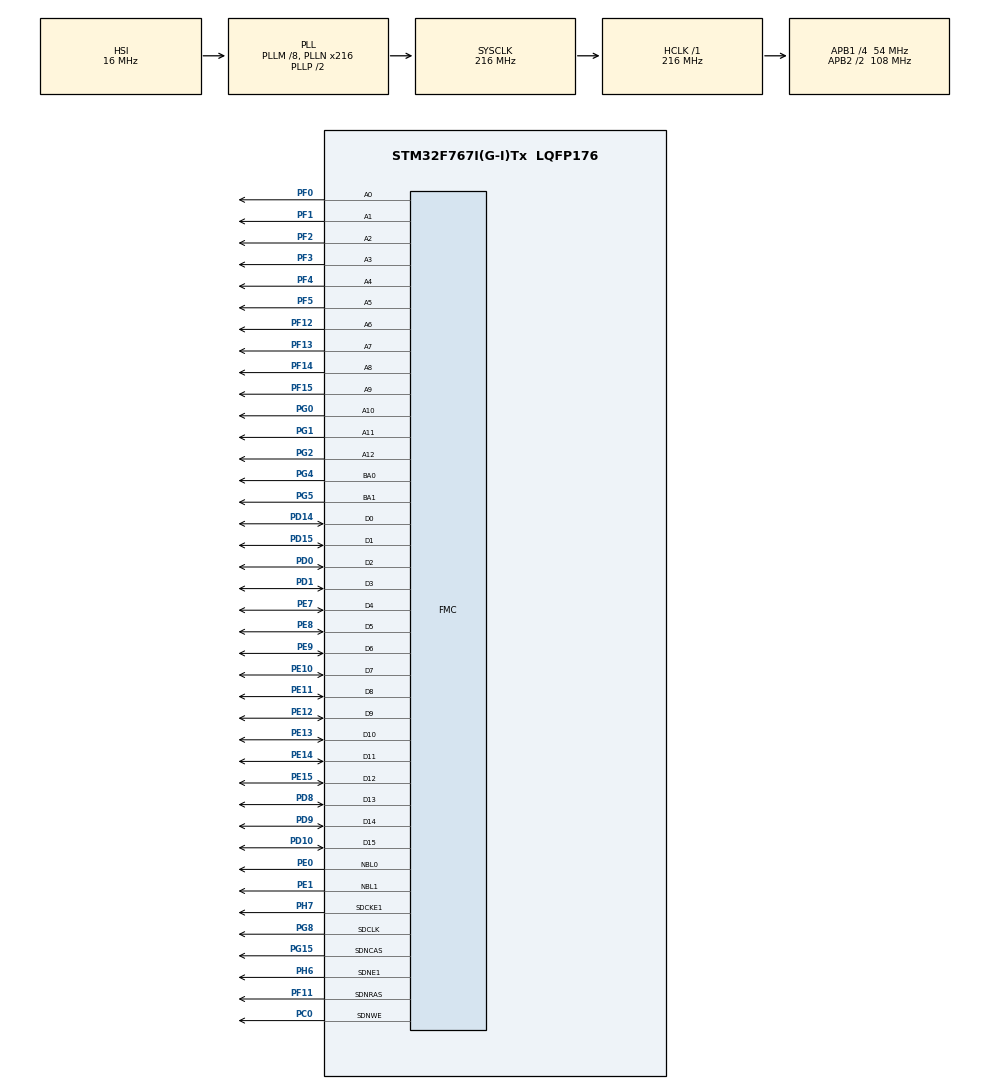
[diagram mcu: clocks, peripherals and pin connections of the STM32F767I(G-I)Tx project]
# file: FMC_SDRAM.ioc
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FMC.CASLatency2=FMC_SDRAM_CAS_LATENCY_3
FMC.ColumnBitsNumber2=FMC_SDRAM_COLUMN_BITS_NUM_9
FMC.ExitSelfRefreshDelay2=9
FMC.LoadToActiveDelay2=2
FMC.RCDDelay2=3
FMC.RPDelay1=3
FMC.RPDelay2=3
FMC.RowCycleDelay1=8
FMC.RowCycleDelay2=8
FMC.SDClockPeriod1=FMC_SDRAM_CLOCK_PERIOD_2
FMC.SDClockPeriod2=FMC_SDRAM_CLOCK_PERIOD_2
FMC.SelfRefreshTime2=6
FMC.WriteRecoveryTime2=3
Mcu.Family=STM32F7
Mcu.Name=STM32F767I(G-I)Tx
Mcu.Package=LQFP176
NVIC.PriorityGroup=NVIC_PRIORITYGROUP_4
PA13.Mode=Serial_Wire
PA13.Signal=SYS_JTMS-SWDIO
PA14.Mode=Serial_Wire
PA14.Signal=SYS_JTCK-SWCLK
PC0.Signal=FMC_SDNWE
PD0.Signal=FMC_D2_DA2
PD1.Signal=FMC_D3_DA3
PD10.Signal=FMC_D15_DA15
PD14.Signal=FMC_D0_DA0
PD15.Signal=FMC_D1_DA1
PD8.Signal=FMC_D13_DA13
PD9.Signal=FMC_D14_DA14
PE0.Signal=FMC_NBL0
PE1.Signal=FMC_NBL1
PE10.Signal=FMC_D7_DA7
PE11.Signal=FMC_D8_DA8
PE12.Signal=FMC_D9_DA9
PE13.Signal=FMC_D10_DA10
PE14.Signal=FMC_D11_DA11
PE15.Signal=FMC_D12_DA12
PE7.Signal=FMC_D4_DA4
PE8.Signal=FMC_D5_DA5
PE9.Signal=FMC_D6_DA6
PF0.Signal=FMC_A0
PF1.Signal=FMC_A1
PF11.Signal=FMC_SDNRAS
PF12.Signal=FMC_A6
PF13.Signal=FMC_A7
PF14.Signal=FMC_A8
PF15.Signal=FMC_A9
PF2.Signal=FMC_A2
PF3.Signal=FMC_A3
PF4.Signal=FMC_A4
PF5.Signal=FMC_A5
PG0.Signal=FMC_A10
PG1.Signal=FMC_A11
PG15.Signal=FMC_SDNCAS
PG2.Signal=FMC_A12
PG4.Signal=FMC_A14_BA0
PG5.Signal=FMC_A15_BA1
PG8.Signal=FMC_SDCLK
PH0/OSC_IN.Mode=HSE-External-Oscillator
PH0/OSC_IN.Signal=RCC_OSC_IN
PH1/OSC_OUT.Mode=HSE-External-Oscillator
PH1/OSC_OUT.Signal=RCC_OSC_OUT
PH6.Mode=SdramChipSelect2_2
PH6.Signal=FMC_SDNE1
PH7.Mode=SdramChipSelect2_2
PH7.Signal=FMC_SDCKE1
ProjectManager.HeapSize=0x200
ProjectManager.StackSize=0x400
ProjectManager.TargetToolchain=MDK-ARM V5.32
RCC.AHBFreq_Value=216000000
RCC.APB1CLKDivider=RCC_HCLK_DIV4
RCC.APB1Freq_Value=54000000
RCC.APB1TimFreq_Value=108000000
RCC.APB2CLKDivider=RCC_HCLK_DIV2
RCC.APB2Freq_Value=108000000
RCC.APB2TimFreq_Value=216000000
RCC.CortexFreq_Value=216000000
RCC.HCLKFreq_Value=216000000
RCC.HSE_VALUE=25000000
RCC.HSI_VALUE=16000000
RCC.LSE_VALUE=32768
RCC.PLLM=8
RCC.PLLN=216
RCC.SYSCLKFreq_VALUE=216000000
RCC.SYSCLKSource=RCC_SYSCLKSOURCE_PLLCLK
RCC.USBFreq_Value=216000000
RCC.VCOOutputFreq_Value=432000000
SH.FMC_A0.0=FMC_A0,13b-sda2
SH.FMC_A1.0=FMC_A1,13b-sda2
SH.FMC_A10.0=FMC_A10,13b-sda2
SH.FMC_A11.0=FMC_A11,13b-sda2
SH.FMC_A12.0=FMC_A12,13b-sda2
SH.FMC_A14_BA0.0=FMC_BA0,FourSdramBanks2
SH.FMC_A15_BA1.0=FMC_BA1,FourSdramBanks2
SH.FMC_A2.0=FMC_A2,13b-sda2
SH.FMC_A3.0=FMC_A3,13b-sda2
SH.FMC_A4.0=FMC_A4,13b-sda2
SH.FMC_A5.0=FMC_A5,13b-sda2
SH.FMC_A6.0=FMC_A6,13b-sda2
SH.FMC_A7.0=FMC_A7,13b-sda2
SH.FMC_A8.0=FMC_A8,13b-sda2
SH.FMC_A9.0=FMC_A9,13b-sda2
SH.FMC_D0_DA0.0=FMC_D0,sd-16b-d2
SH.FMC_D10_DA10.0=FMC_D10,sd-16b-d2
SH.FMC_D11_DA11.0=FMC_D11,sd-16b-d2
SH.FMC_D12_DA12.0=FMC_D12,sd-16b-d2
SH.FMC_D13_DA13.0=FMC_D13,sd-16b-d2
SH.FMC_D14_DA14.0=FMC_D14,sd-16b-d2
SH.FMC_D15_DA15.0=FMC_D15,sd-16b-d2
SH.FMC_D1_DA1.0=FMC_D1,sd-16b-d2
SH.FMC_D2_DA2.0=FMC_D2,sd-16b-d2
SH.FMC_D3_DA3.0=FMC_D3,sd-16b-d2
SH.FMC_D4_DA4.0=FMC_D4,sd-16b-d2
SH.FMC_D5_DA5.0=FMC_D5,sd-16b-d2
SH.FMC_D6_DA6.0=FMC_D6,sd-16b-d2
SH.FMC_D7_DA7.0=FMC_D7,sd-16b-d2
SH.FMC_D8_DA8.0=FMC_D8,sd-16b-d2
SH.FMC_D9_DA9.0=FMC_D9,sd-16b-d2
SH.FMC_NBL0.0=FMC_NBL0,Sd2ByteEnable2
SH.FMC_NBL1.0=FMC_NBL1,Sd2ByteEnable2
SH.FMC_SDCLK.0=FMC_SDCLK,13b-sda2
SH.FMC_SDNCAS.0=FMC_SDNCAS,13b-sda2
SH.FMC_SDNRAS.0=FMC_SDNRAS,13b-sda2
SH.FMC_SDNWE.0=FMC_SDNWE,13b-sda2
board=custom

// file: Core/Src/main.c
/* USER CODE BEGIN Header */
/**
  ******************************************************************************
  * @file           : main.c
  * @brief          : Main program body
  ******************************************************************************
  * @attention
  *
  * Copyright (c) 2023 STMicroelectronics.
  * All rights reserved.
  *
  * This software is licensed under terms that can be found in the LICENSE file
  * in the root directory of this software component.
  * If no LICENSE file comes with this software, it is provided AS-IS.
  *
  ******************************************************************************
  */
/* USER CODE END Header */
#include "main.h"
#include "gpio.h"
#include "fmc.h"

void SystemClock_Config(void);
static void MPU_Config(void);

/* USER CODE BEGIN 0 */
uint32_t pbuff[(32*1024*1024)/4] __attribute__((at(0xD0000000)));

/* USER CODE END 0 */

int main(void)
{

  /* MPU Configuration--------------------------------------------------------*/
  MPU_Config();

  /* MCU Configuration--------------------------------------------------------*/

  /* Reset of all peripherals, Initializes the Flash interface and the Systick. */
  HAL_Init();

  /* Configure the system clock */
  SystemClock_Config();

  /* Initialize all configured peripherals */
  MX_GPIO_Init();
  MX_FMC_Init();
  /* USER CODE BEGIN 2 */

	for(int count =0;count<0x20000000/4;count++)
		pbuff[count] = count;

	for(int count =0;count<0x20000000/4;count++)
	{
		if(pbuff[count] != count)
		{
			goto checkFailed;
		}
	}

  /* USER CODE END 2 */

  /* Infinite loop */
  while (1)
  {

    /* USER CODE BEGIN 3 */
  }
checkFailed:
	while(1);
  /* USER CODE END 3 */
}

void SystemClock_Config(void)
{
  RCC_OscInitTypeDef RCC_OscInitStruct = {0};
  RCC_ClkInitTypeDef RCC_ClkInitStruct = {0};

  /** Configure the main internal regulator output voltage
  */
  __HAL_RCC_PWR_CLK_ENABLE();
  __HAL_PWR_VOLTAGESCALING_CONFIG(PWR_REGULATOR_VOLTAGE_SCALE1);

  /** Initializes the RCC Oscillators according to the specified parameters
  * in the RCC_OscInitTypeDef structure.
  */
  RCC_OscInitStruct.OscillatorType = RCC_OSCILLATORTYPE_HSI;
  RCC_OscInitStruct.HSIState = RCC_HSI_ON;
  RCC_OscInitStruct.HSICalibrationValue = RCC_HSICALIBRATION_DEFAULT;
  RCC_OscInitStruct.PLL.PLLState = RCC_PLL_ON;
  RCC_OscInitStruct.PLL.PLLSource = RCC_PLLSOURCE_HSI;
  RCC_OscInitStruct.PLL.PLLM = 8;
  RCC_OscInitStruct.PLL.PLLN = 216;
  RCC_OscInitStruct.PLL.PLLP = RCC_PLLP_DIV2;
  RCC_OscInitStruct.PLL.PLLQ = 2;
  RCC_OscInitStruct.PLL.PLLR = 2;
  if (HAL_RCC_OscConfig(&RCC_OscInitStruct) != HAL_OK)
  {
    Error_Handler();
  }

  /** Activate the Over-Drive mode
  */
  if (HAL_PWREx_EnableOverDrive() != HAL_OK)
  {
    Error_Handler();
  }

  /** Initializes the CPU, AHB and APB buses clocks
  */
  RCC_ClkInitStruct.ClockType = RCC_CLOCKTYPE_HCLK|RCC_CLOCKTYPE_SYSCLK
                              |RCC_CLOCKTYPE_PCLK1|RCC_CLOCKTYPE_PCLK2;
  RCC_ClkInitStruct.SYSCLKSource = RCC_SYSCLKSOURCE_PLLCLK;
  RCC_ClkInitStruct.AHBCLKDivider = RCC_SYSCLK_DIV1;
  RCC_ClkInitStruct.APB1CLKDivider = RCC_HCLK_DIV4;
  RCC_ClkInitStruct.APB2CLKDivider = RCC_HCLK_DIV2;

  if (HAL_RCC_ClockConfig(&RCC_ClkInitStruct, FLASH_LATENCY_7) != HAL_OK)
  {
    Error_Handler();
  }
}

/* MPU Configuration */

void MPU_Config(void)
{
  MPU_Region_InitTypeDef MPU_InitStruct = {0};

  /* Disables the MPU */
  HAL_MPU_Disable();

  /** Initializes and configures the Region and the memory to be protected
  */
  MPU_InitStruct.Enable = MPU_REGION_ENABLE;
  MPU_InitStruct.Number = MPU_REGION_NUMBER0;
  MPU_InitStruct.BaseAddress = 0x0;
  MPU_InitStruct.Size = MPU_REGION_SIZE_4GB;
  MPU_InitStruct.SubRegionDisable = 0x87;
  MPU_InitStruct.TypeExtField = MPU_TEX_LEVEL0;
  MPU_InitStruct.AccessPermission = MPU_REGION_NO_ACCESS;
  MPU_InitStruct.DisableExec = MPU_INSTRUCTION_ACCESS_DISABLE;
  MPU_InitStruct.IsShareable = MPU_ACCESS_SHAREABLE;
  MPU_InitStruct.IsCacheable = MPU_ACCESS_NOT_CACHEABLE;
  MPU_InitStruct.IsBufferable = MPU_ACCESS_NOT_BUFFERABLE;

  HAL_MPU_ConfigRegion(&MPU_InitStruct);
  /* Enables the MPU */
  HAL_MPU_Enable(MPU_PRIVILEGED_DEFAULT);

}

void Error_Handler(void)
{
  __disable_irq();
  while (1)
  {
  }
}
